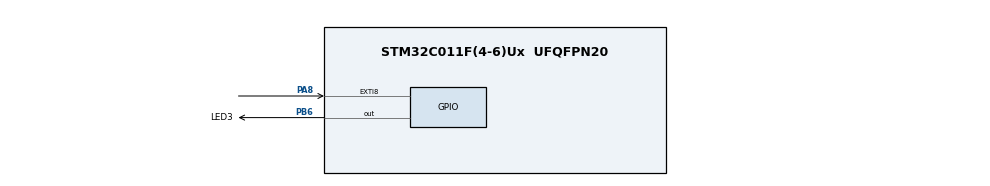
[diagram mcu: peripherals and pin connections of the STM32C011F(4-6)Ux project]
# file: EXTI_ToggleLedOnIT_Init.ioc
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Mcu.Family=STM32C0
Mcu.Name=STM32C011F(4-6)Ux
Mcu.Package=UFQFPN20
NVIC.EXTI4_15_IRQn=true\:0\:0\:false\:false\:true\:true\:true\:true
PA8.GPIO_ModeDefaultEXTI=GPIO_MODE_IT_FALLING
PA8.Signal=GPXTI8
PB6.GPIO_Label=LED3
PB6.PinState=GPIO_PIN_SET
PB6.Signal=GPIO_Output
ProjectManager.HeapSize=0x200
ProjectManager.StackSize=0x400
ProjectManager.TargetToolchain=EWARM V9.20
RCC.ADCFreq_Value=48000000
RCC.AHBFreq_Value=48000000
RCC.CortexFreq_Value=48000000
RCC.EXTERNAL_CLOCK_VALUE=12288000
RCC.HCLKFreq_Value=48000000
RCC.HSE_VALUE=8000000
RCC.HSISYSCLKDivider=RCC_HSI_DIV1
RCC.HSI_VALUE=48000000
RCC.LSE_VALUE=32768
RCC.SYSCLKFreq_VALUE=48000000
board=custom

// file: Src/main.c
/* USER CODE BEGIN Header */
/**
  ******************************************************************************
  * @file    Examples_LL/EXTI/EXTI_ToggleLedOnIT_Init/Src/main.c
  * @author  MCD Application Team
  * @brief   This example describes how to configure the EXTI and use
  *          GPIOs using the STM32C0xx LL API to toggles the available
  *          users Leds on the board when User button is pressed.
  *          Peripheral initialization done using LL initialization function.
  ******************************************************************************
  * @attention
  *
  * Copyright (c) 2022 STMicroelectronics.
  * All rights reserved.
  *
  * This software is licensed under terms that can be found in the LICENSE file
  * in the root directory of this software component.
  * If no LICENSE file comes with this software, it is provided AS-IS.
  *
  ******************************************************************************
  */
/* USER CODE END Header */
#include "main.h"

void SystemClock_Config(void);
static void MX_GPIO_Init(void);

int main(void)
{

  /* MCU Configuration--------------------------------------------------------*/

  /* Reset of all peripherals, Initializes the Flash interface and the Systick. */
  LL_APB2_GRP1_EnableClock(LL_APB2_GRP1_PERIPH_SYSCFG);
  LL_APB1_GRP1_EnableClock(LL_APB1_GRP1_PERIPH_PWR);

  /* Configure the system clock */
  SystemClock_Config();

  /* Initialize all configured peripherals */
  MX_GPIO_Init();

  /* Infinite loop */
  while (1)
  {

  }
}

void SystemClock_Config(void)
{

  LL_FLASH_SetLatency(LL_FLASH_LATENCY_1);

  /* HSI configuration and activation */
  LL_RCC_HSI_Enable();
  while(LL_RCC_HSI_IsReady() != 1)
  {
  }

  LL_RCC_HSI_SetCalibTrimming(64);
  LL_RCC_SetHSIDiv(LL_RCC_HSI_DIV_1);
  /* Set AHB prescaler*/
  LL_RCC_SetAHBPrescaler(LL_RCC_HCLK_DIV_1);

  /* Sysclk activation on the HSI */
  LL_RCC_SetSysClkSource(LL_RCC_SYS_CLKSOURCE_HSI);
  while(LL_RCC_GetSysClkSource() != LL_RCC_SYS_CLKSOURCE_STATUS_HSI)
  {
  }

  /* Set APB1 prescaler*/
  LL_RCC_SetAPB1Prescaler(LL_RCC_APB1_DIV_1);
  LL_Init1msTick(48000000);
  /* Update CMSIS variable (which can be updated also through SystemCoreClockUpdate function) */
  LL_SetSystemCoreClock(48000000);
}

static void MX_GPIO_Init(void)
{
  LL_EXTI_InitTypeDef EXTI_InitStruct = {0};
  LL_GPIO_InitTypeDef GPIO_InitStruct = {0};

  /* GPIO Ports Clock Enable */
  LL_IOP_GRP1_EnableClock(LL_IOP_GRP1_PERIPH_GPIOA);
  LL_IOP_GRP1_EnableClock(LL_IOP_GRP1_PERIPH_GPIOB);

  /**/
  LL_GPIO_SetOutputPin(LED3_GPIO_Port, LED3_Pin);

  /**/
  EXTI_InitStruct.Line_0_31 = LL_EXTI_LINE_8;
  EXTI_InitStruct.LineCommand = ENABLE;
  EXTI_InitStruct.Mode = LL_EXTI_MODE_IT;
  EXTI_InitStruct.Trigger = LL_EXTI_TRIGGER_FALLING;
  LL_EXTI_Init(&EXTI_InitStruct);

  /**/
  LL_GPIO_SetPinMode(GPIOA, LL_GPIO_PIN_8, LL_GPIO_MODE_INPUT);

  /**/
  LL_GPIO_SetPinPull(GPIOA, LL_GPIO_PIN_8, LL_GPIO_PULL_NO);

  /**/
  LL_EXTI_SetEXTISource(LL_EXTI_CONFIG_PORTA, LL_EXTI_CONFIG_LINE8);

  /**/
  GPIO_InitStruct.Pin = LED3_Pin;
  GPIO_InitStruct.Mode = LL_GPIO_MODE_OUTPUT;
  GPIO_InitStruct.Speed = LL_GPIO_SPEED_FREQ_LOW;
  GPIO_InitStruct.OutputType = LL_GPIO_OUTPUT_PUSHPULL;
  GPIO_InitStruct.Pull = LL_GPIO_PULL_NO;
  LL_GPIO_Init(LED3_GPIO_Port, &GPIO_InitStruct);

  /* EXTI interrupt init*/
  NVIC_SetPriority(EXTI4_15_IRQn, 0);
  NVIC_EnableIRQ(EXTI4_15_IRQn);

}

/* USER CODE BEGIN 4 */

/******************************************************************************/
/*   USER IRQ HANDLER TREATMENT                                               */
/******************************************************************************/
/**
  * @brief  Function to manage IRQ Handler
  * @param  None
  * @retval None
  */
void UserButton_Callback(void)
{
  LL_GPIO_TogglePin(LED3_GPIO_Port, LED3_Pin);
}

/* USER CODE END 4 */

void Error_Handler(void)
{
}
